# dio register map
Vendor: Texas Instruments
Peripheral module from a debugger description file (folder MSP432).
Registers are 16-bit, read-write, no defined reset value unless marked. A register's access mark holds for its fields unless they carry their own. Offsets are as the file gives them; lines under a group give offsets from that group; [hi:lo] are bit positions; {n}, {i} and the like mark numbered series; 'fields as' and 'values as' point back to an identical list; <NAME> marks a mode.

## DIO
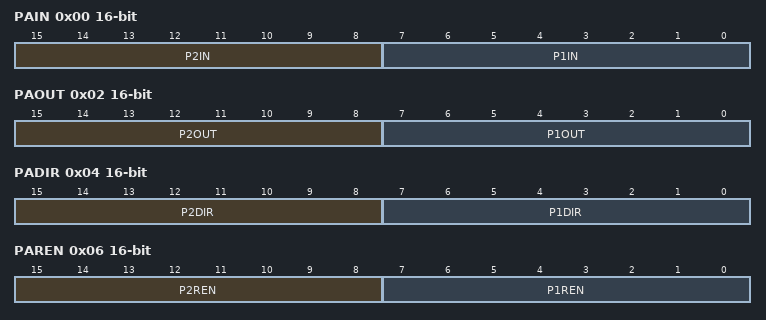
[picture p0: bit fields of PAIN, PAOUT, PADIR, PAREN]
0x00 PAIN — Port A Input
  [15:8] P2IN — Port 2 Input
  [7:0] P1IN — Port 1 Input
0x02 PAOUT — Port A Output
  [15:8] P2OUT — Port 2 Output
  [7:0] P1OUT — Port 1 Output
0x04 PADIR — Port A Direction
  [15:8] P2DIR — Port 2 Direction 0b = Port configured as input 1b = Port conf
  [7:0] P1DIR — Port 1 Direction 0b = Port configured as input 1b = Port conf
0x06 PAREN — Port A Resistor Enable
  [15:8] P2REN — Port 2 pullup or pulldown resistor enable
  [7:0] P1REN — Port 1 pullup or pulldown resistor enable
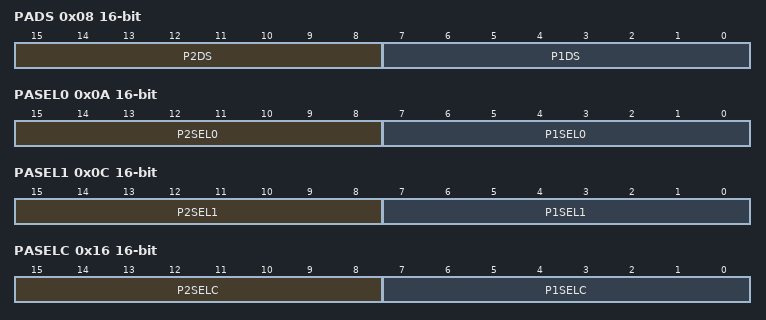
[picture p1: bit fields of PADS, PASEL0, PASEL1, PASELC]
0x08 PADS — Port A Drive Strength
  [15:8] P2DS — Port 2 drive strength selection (for high drive strength I/Os)
  [7:0] P1DS — Port 1 drive strength selection (for high drive strength I/Os)
0x0A PASEL0 — Port A Select 0
  [15:8] P2SEL0 — Port function selection
  [7:0] P1SEL0 — Port function selection
0x0C PASEL1 — Port A Select 1
  [15:8] P2SEL1 — Port function selection
  [7:0] P1SEL1 — Port function selection
0x0E P1IV — Port 1 Interrupt Vector Register
  [4:0] P1IV — Port 1 interrupt vector value
    0=P1IV__0 (No interrupt pending); 2=P1IV__2 (Interrupt Source: Port 1); 4=P1IV__4 (Interrupt Source: Port 1.1 interrupt; Interrupt Flag: P1IFG1); 6=P1IV__6 (Interrupt Source: Port 1.2 interrupt; Interrupt Flag: P1IFG2); 8=P1IV__8 (Interrupt Source: Port 1.3 interrupt; Interrupt Flag: P1IFG3); 10=P1IV__16 (Interrupt Source: Port 1.4 interrupt; Interrupt Flag: P1IFG4); 12=P1IV__18 (Interrupt Source: Port 1.5 interrupt; Interrupt Flag: P1IFG5); 14=P1IV__20 (Interrupt Source: Port 1.6 interrupt; Interrupt Flag: P1IFG6); 16=P1IV__22 (Interrupt Source: Port 1)
0x16 PASELC — Port A Complement Select
  [15:8] P2SELC — Port selection complement
  [7:0] P1SELC — Port selection complement
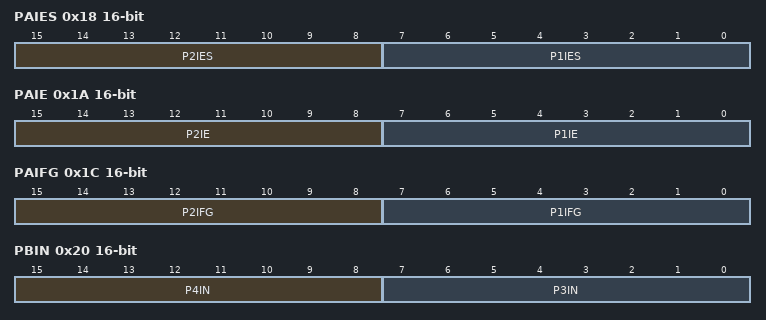
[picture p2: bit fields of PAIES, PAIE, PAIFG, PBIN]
0x18 PAIES — Port A Interrupt Edge Select
  [15:8] P2IES — Port 2 interrupt edge select 0b = PxIFG flag is set with a low
  [7:0] P1IES — Port 1 interrupt edge select 0b = PxIFG flag is set with a low
0x1A PAIE — Port A Interrupt Enable
  [15:8] P2IE — Port 2 Interrupt Enable 0b = Corresponding port interrupt disa
  [7:0] P1IE — Port 1 Interrupt Enable 0b = Corresponding port interrupt disa
0x1C PAIFG — Port A Interrupt Flag
  [15:8] P2IFG — Port 2 Interrupt Flag 0b = No interrupt is pending
  [7:0] P1IFG — Port 1 Interrupt Flag 0b = No interrupt is pending
0x1E P2IV — Port 2 Interrupt Vector Register
  [4:0] P2IV — Port 2 interrupt vector value
    0=P2IV__0 (No interrupt pending); 2=P2IV__2 (Interrupt Source: Port 2); 4=P2IV__4 (Interrupt Source: Port 2.1 interrupt; Interrupt Flag: P2IFG1); 6=P2IV__6 (Interrupt Source: Port 2.2 interrupt; Interrupt Flag: P2IFG2); 8=P2IV__8 (Interrupt Source: Port 2.3 interrupt; Interrupt Flag: P2IFG3); 10=P2IV__16 (Interrupt Source: Port 2.4 interrupt; Interrupt Flag: P2IFG4); 12=P2IV__18 (Interrupt Source: Port 2.5 interrupt; Interrupt Flag: P2IFG5); 14=P2IV__20 (Interrupt Source: Port 2.6 interrupt; Interrupt Flag: P2IFG6); 16=P2IV__22 (Interrupt Source: Port 2)
0x20 PBIN — Port B Input
  [15:8] P4IN — Port 4 Input
  [7:0] P3IN — Port 3 Input
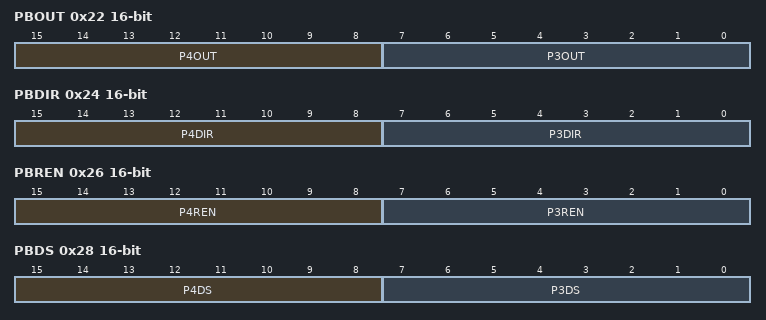
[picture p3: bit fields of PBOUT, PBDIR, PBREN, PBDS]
0x22 PBOUT — Port B Output
  [15:8] P4OUT — Port 4 Output
  [7:0] P3OUT — Port 3 Output
0x24 PBDIR — Port B Direction
  [15:8] P4DIR — Port 4 Direction 0b = Port configured as input 1b = Port conf
  [7:0] P3DIR — Port 3 Direction 0b = Port configured as input 1b = Port conf
0x26 PBREN — Port B Resistor Enable
  [15:8] P4REN — Port 4 pullup or pulldown resistor enable
  [7:0] P3REN — Port 3 pullup or pulldown resistor enable
0x28 PBDS — Port B Drive Strength
  [15:8] P4DS — Port 4 drive strength selection (for high drive strength I/Os)
  [7:0] P3DS — Port 3 drive strength selection (for high drive strength I/Os)
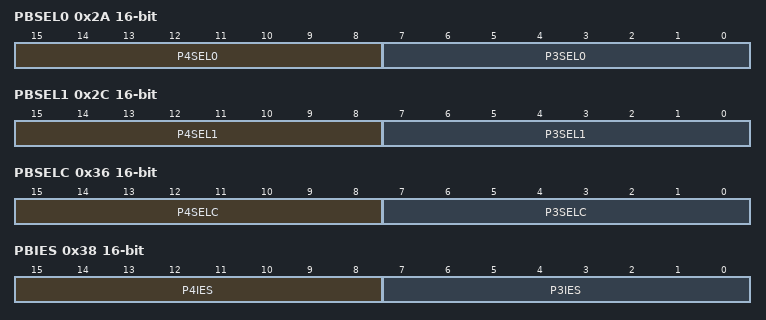
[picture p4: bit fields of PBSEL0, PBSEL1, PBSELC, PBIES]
0x2A PBSEL0 — Port B Select 0
  [15:8] P4SEL0 — Port function selection
  [7:0] P3SEL0 — Port function selection
0x2C PBSEL1 — Port B Select 1
  [15:8] P4SEL1 — Port function selection
  [7:0] P3SEL1 — Port function selection
0x2E P3IV — Port 3 Interrupt Vector Register
  [4:0] P3IV — Port 3 interrupt vector value
    0=P3IV__0 (No interrupt pending); 2=P3IV__2 (Interrupt Source: Port 3); 4=P3IV__4 (Interrupt Source: Port 3.1 interrupt; Interrupt Flag: P3IFG1); 6=P3IV__6 (Interrupt Source: Port 3.2 interrupt; Interrupt Flag: P3IFG2); 8=P3IV__8 (Interrupt Source: Port 3.3 interrupt; Interrupt Flag: P3IFG3); 10=P3IV__16 (Interrupt Source: Port 3.4 interrupt; Interrupt Flag: P3IFG4); 12=P3IV__18 (Interrupt Source: Port 3.5 interrupt; Interrupt Flag: P3IFG5); 14=P3IV__20 (Interrupt Source: Port 3.6 interrupt; Interrupt Flag: P3IFG6); 16=P3IV__22 (Interrupt Source: Port 3)
0x36 PBSELC — Port B Complement Select
  [15:8] P4SELC — Port selection complement
  [7:0] P3SELC — Port selection complement
0x38 PBIES — Port B Interrupt Edge Select
  [15:8] P4IES — Port 4 interrupt edge select 0b = PxIFG flag is set with a low
  [7:0] P3IES — Port 3 interrupt edge select 0b = PxIFG flag is set with a low
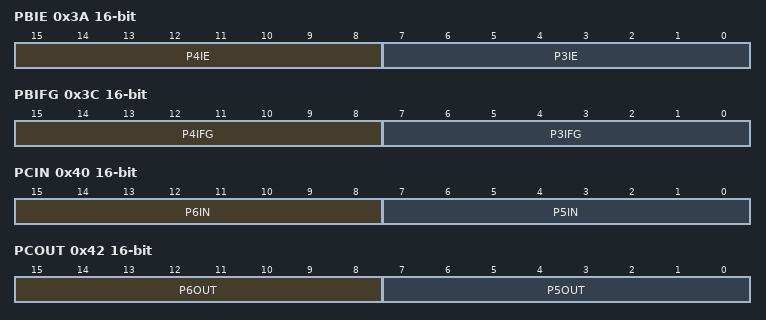
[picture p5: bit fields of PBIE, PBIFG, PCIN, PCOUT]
0x3A PBIE — Port B Interrupt Enable
  [15:8] P4IE — Port 4 Interrupt Enable 0b = Corresponding port interrupt disa
  [7:0] P3IE — Port 3 Interrupt Enable 0b = Corresponding port interrupt disa
0x3C PBIFG — Port B Interrupt Flag
  [15:8] P4IFG — Port 4 Interrupt Flag 0b = No interrupt is pending
  [7:0] P3IFG — Port 3 Interrupt Flag 0b = No interrupt is pending
0x3E P4IV — Port 4 Interrupt Vector Register
  [4:0] P4IV — Port 4 interrupt vector value
    0=P4IV__0 (No interrupt pending); 2=P4IV__2 (Interrupt Source: Port 4); 4=P4IV__4 (Interrupt Source: Port 4.1 interrupt; Interrupt Flag: P4IFG1); 6=P4IV__6 (Interrupt Source: Port 4.2 interrupt; Interrupt Flag: P4IFG2); 8=P4IV__8 (Interrupt Source: Port 4.3 interrupt; Interrupt Flag: P4IFG3); 10=P4IV__16 (Interrupt Source: Port 4.4 interrupt; Interrupt Flag: P4IFG4); 12=P4IV__18 (Interrupt Source: Port 4.5 interrupt; Interrupt Flag: P4IFG5); 14=P4IV__20 (Interrupt Source: Port 4.6 interrupt; Interrupt Flag: P4IFG6); 16=P4IV__22 (Interrupt Source: Port 4)
0x40 PCIN — Port C Input
  [15:8] P6IN — Port 6 Input
  [7:0] P5IN — Port 5 Input
0x42 PCOUT — Port C Output
  [15:8] P6OUT — Port 6 Output
  [7:0] P5OUT — Port 5 Output
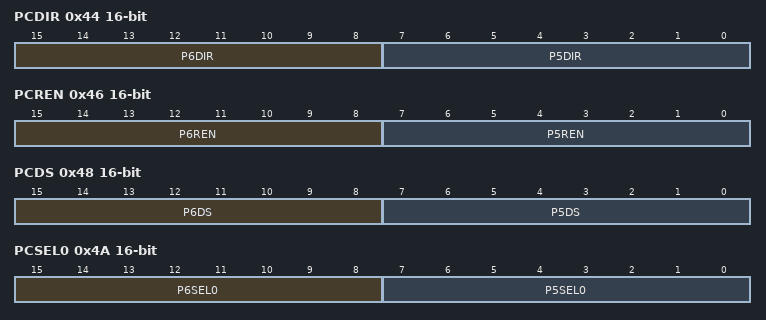
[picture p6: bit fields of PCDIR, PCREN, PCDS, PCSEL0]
0x44 PCDIR — Port C Direction
  [15:8] P6DIR — Port 6 Direction 0b = Port configured as input 1b = Port conf
  [7:0] P5DIR — Port 5 Direction 0b = Port configured as input 1b = Port conf
0x46 PCREN — Port C Resistor Enable
  [15:8] P6REN — Port 6 pullup or pulldown resistor enable
  [7:0] P5REN — Port 5 pullup or pulldown resistor enable
0x48 PCDS — Port C Drive Strength
  [15:8] P6DS — Port 6 drive strength selection (for high drive strength I/Os)
  [7:0] P5DS — Port 5 drive strength selection (for high drive strength I/Os)
0x4A PCSEL0 — Port C Select 0
  [15:8] P6SEL0 — Port function selection
  [7:0] P5SEL0 — Port function selection
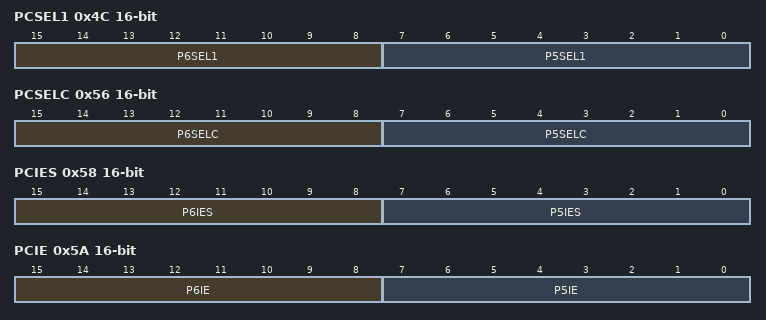
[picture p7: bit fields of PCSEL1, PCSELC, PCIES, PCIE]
0x4C PCSEL1 — Port C Select 1
  [15:8] P6SEL1 — Port function selection
  [7:0] P5SEL1 — Port function selection
0x4E P5IV — Port 5 Interrupt Vector Register
  [4:0] P5IV — Port 5 interrupt vector value
    0=P5IV__0 (No interrupt pending); 2=P5IV__2 (Interrupt Source: Port 5); 4=P5IV__4 (Interrupt Source: Port 5.1 interrupt; Interrupt Flag: P5IFG1); 6=P5IV__6 (Interrupt Source: Port 5.2 interrupt; Interrupt Flag: P5IFG2); 8=P5IV__8 (Interrupt Source: Port 5.3 interrupt; Interrupt Flag: P5IFG3); 10=P5IV__16 (Interrupt Source: Port 5.4 interrupt; Interrupt Flag: P5IFG4); 12=P5IV__18 (Interrupt Source: Port 5.5 interrupt; Interrupt Flag: P5IFG5); 14=P5IV__20 (Interrupt Source: Port 5.6 interrupt; Interrupt Flag: P5IFG6); 16=P5IV__22 (Interrupt Source: Port 5)
0x56 PCSELC — Port C Complement Select
  [15:8] P6SELC — Port selection complement
  [7:0] P5SELC — Port selection complement
0x58 PCIES — Port C Interrupt Edge Select
  [15:8] P6IES — Port 6 interrupt edge select 0b = PxIFG flag is set with a low
  [7:0] P5IES — Port 5 interrupt edge select 0b = PxIFG flag is set with a low
0x5A PCIE — Port C Interrupt Enable
  [15:8] P6IE — Port 6 Interrupt Enable 0b = Corresponding port interrupt disa
  [7:0] P5IE — Port 5 Interrupt Enable 0b = Corresponding port interrupt disa
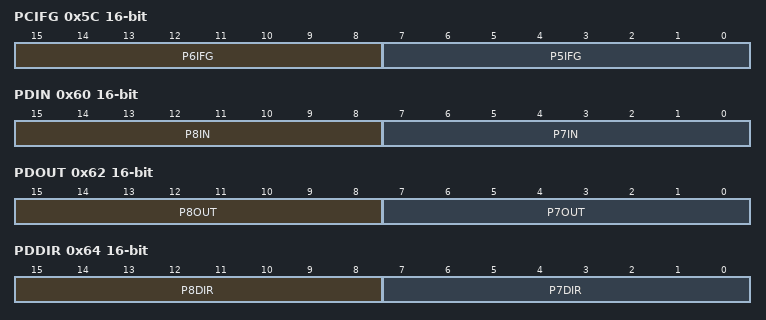
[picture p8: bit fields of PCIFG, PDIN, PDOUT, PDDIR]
0x5C PCIFG — Port C Interrupt Flag
  [15:8] P6IFG — Port 6 Interrupt Flag 0b = No interrupt is pending
  [7:0] P5IFG — Port 5 Interrupt Flag 0b = No interrupt is pending
0x5E P6IV — Port 6 Interrupt Vector Register
  [4:0] P6IV — Port 6 interrupt vector value
    0=P6IV__0 (No interrupt pending); 2=P6IV__2 (Interrupt Source: Port 6); 4=P6IV__4 (Interrupt Source: Port 6.1 interrupt; Interrupt Flag: P6IFG1); 6=P6IV__6 (Interrupt Source: Port 6.2 interrupt; Interrupt Flag: P6IFG2); 8=P6IV__8 (Interrupt Source: Port 6.3 interrupt; Interrupt Flag: P6IFG3); 10=P6IV__16 (Interrupt Source: Port 6.4 interrupt; Interrupt Flag: P6IFG4); 12=P6IV__18 (Interrupt Source: Port 6.5 interrupt; Interrupt Flag: P6IFG5); 14=P6IV__20 (Interrupt Source: Port 6.6 interrupt; Interrupt Flag: P6IFG6); 16=P6IV__22 (Interrupt Source: Port 6)
0x60 PDIN — Port D Input
  [15:8] P8IN — Port 8 Input
  [7:0] P7IN — Port 7 Input
0x62 PDOUT — Port D Output
  [15:8] P8OUT — Port 8 Output
  [7:0] P7OUT — Port 7 Output
0x64 PDDIR — Port D Direction
  [15:8] P8DIR — Port 8 Direction 0b = Port configured as input 1b = Port conf
  [7:0] P7DIR — Port 7 Direction 0b = Port configured as input 1b = Port conf
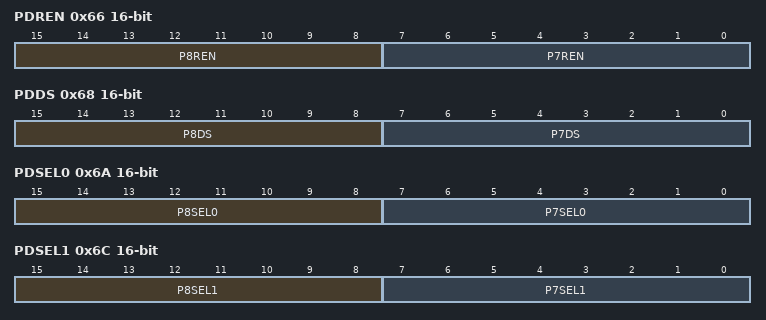
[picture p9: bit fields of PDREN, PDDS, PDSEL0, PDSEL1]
0x66 PDREN — Port D Resistor Enable
  [15:8] P8REN — Port 8 pullup or pulldown resistor enable
  [7:0] P7REN — Port 7 pullup or pulldown resistor enable
0x68 PDDS — Port D Drive Strength
  [15:8] P8DS — Port 8 drive strength selection (for high drive strength I/Os)
  [7:0] P7DS — Port 7 drive strength selection (for high drive strength I/Os)
0x6A PDSEL0 — Port D Select 0
  [15:8] P8SEL0 — Port function selection
  [7:0] P7SEL0 — Port function selection
0x6C PDSEL1 — Port D Select 1
  [15:8] P8SEL1 — Port function selection
  [7:0] P7SEL1 — Port function selection
0x6E P7IV — Port 7 Interrupt Vector Register
  [4:0] P7IV — Port 7 interrupt vector value
    0=P7IV__0 (No interrupt pending); 2=P7IV__2 (Interrupt Source: Port 7); 4=P7IV__4 (Interrupt Source: Port 7.1 interrupt; Interrupt Flag: P7IFG1); 6=P7IV__6 (Interrupt Source: Port 7.2 interrupt; Interrupt Flag: P7IFG2); 8=P7IV__8 (Interrupt Source: Port 7.3 interrupt; Interrupt Flag: P7IFG3); 10=P7IV__16 (Interrupt Source: Port 7.4 interrupt; Interrupt Flag: P7IFG4); 12=P7IV__18 (Interrupt Source: Port 7.5 interrupt; Interrupt Flag: P7IFG5); 14=P7IV__20 (Interrupt Source: Port 7.6 interrupt; Interrupt Flag: P7IFG6); 16=P7IV__22 (Interrupt Source: Port 7)
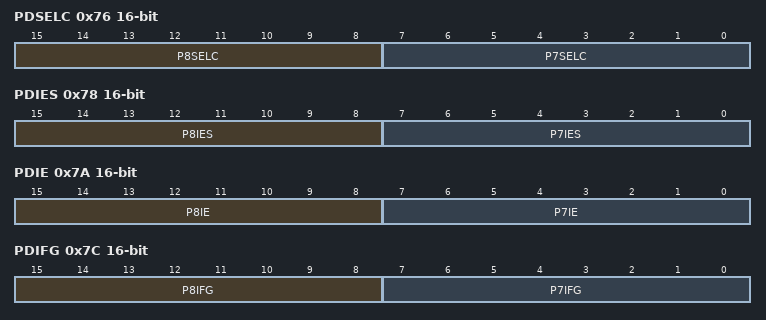
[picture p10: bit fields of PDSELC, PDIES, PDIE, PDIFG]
0x76 PDSELC — Port D Complement Select
  [15:8] P8SELC — Port selection complement
  [7:0] P7SELC — Port selection complement
0x78 PDIES — Port D Interrupt Edge Select
  [15:8] P8IES — Port 8 interrupt edge select 0b = PxIFG flag is set with a low
  [7:0] P7IES — Port 7 interrupt edge select 0b = PxIFG flag is set with a low
0x7A PDIE — Port D Interrupt Enable
  [15:8] P8IE — Port 8 Interrupt Enable 0b = Corresponding port interrupt disa
  [7:0] P7IE — Port 7 Interrupt Enable 0b = Corresponding port interrupt disa
0x7C PDIFG — Port D Interrupt Flag
  [15:8] P8IFG — Port 8 Interrupt Flag 0b = No interrupt is pending
  [7:0] P7IFG — Port 7 Interrupt Flag 0b = No interrupt is pending
0x7E P8IV — Port 8 Interrupt Vector Register
  [4:0] P8IV — Port 8 interrupt vector value
    0=P8IV__0 (No interrupt pending); 2=P8IV__2 (Interrupt Source: Port 8); 4=P8IV__4 (Interrupt Source: Port 8.1 interrupt; Interrupt Flag: P8IFG1); 6=P8IV__6 (Interrupt Source: Port 8.2 interrupt; Interrupt Flag: P8IFG2); 8=P8IV__8 (Interrupt Source: Port 8.3 interrupt; Interrupt Flag: P8IFG3); 10=P8IV__16 (Interrupt Source: Port 8.4 interrupt; Interrupt Flag: P8IFG4); 12=P8IV__18 (Interrupt Source: Port 8.5 interrupt; Interrupt Flag: P8IFG5); 14=P8IV__20 (Interrupt Source: Port 8.6 interrupt; Interrupt Flag: P8IFG6); 16=P8IV__22 (Interrupt Source: Port 8)
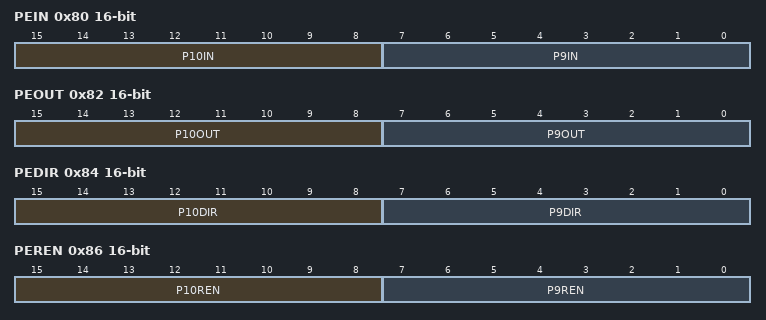
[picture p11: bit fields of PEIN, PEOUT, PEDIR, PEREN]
0x80 PEIN — Port E Input
  [15:8] P10IN — Port 10 Input
  [7:0] P9IN — Port 9 Input
0x82 PEOUT — Port E Output
  [15:8] P10OUT — Port 10 Output
  [7:0] P9OUT — Port 9 Output
0x84 PEDIR — Port E Direction
  [15:8] P10DIR — Port 10 Direction 0b = Port configured as input 1b = Port con
  [7:0] P9DIR — Port 9 Direction 0b = Port configured as input 1b = Port conf
0x86 PEREN — Port E Resistor Enable
  [15:8] P10REN — Port 10 pullup or pulldown resistor enable
  [7:0] P9REN — Port 9 pullup or pulldown resistor enable
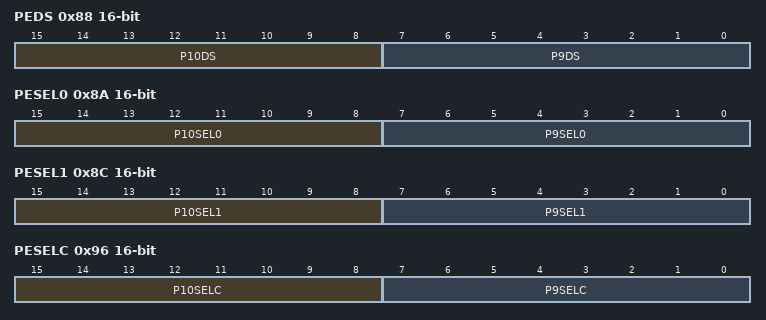
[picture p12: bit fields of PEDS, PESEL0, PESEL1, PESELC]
0x88 PEDS — Port E Drive Strength
  [15:8] P10DS — Port 10 drive strength selection (for high drive strength I/Os)
  [7:0] P9DS — Port 9 drive strength selection (for high drive strength I/Os)
0x8A PESEL0 — Port E Select 0
  [15:8] P10SEL0 — Port function selection
  [7:0] P9SEL0 — Port function selection
0x8C PESEL1 — Port E Select 1
  [15:8] P10SEL1 — Port function selection
  [7:0] P9SEL1 — Port function selection
0x8E P9IV — Port 9 Interrupt Vector Register
  [4:0] P9IV — Port 9 interrupt vector value
    0=P9IV__0 (No interrupt pending); 2=P9IV__2 (Interrupt Source: Port 9); 4=P9IV__4 (Interrupt Source: Port 9.1 interrupt; Interrupt Flag: P9IFG1); 6=P9IV__6 (Interrupt Source: Port 9.2 interrupt; Interrupt Flag: P9IFG2); 8=P9IV__8 (Interrupt Source: Port 9.3 interrupt; Interrupt Flag: P9IFG3); 10=P9IV__16 (Interrupt Source: Port 9.4 interrupt; Interrupt Flag: P9IFG4); 12=P9IV__18 (Interrupt Source: Port 9.5 interrupt; Interrupt Flag: P9IFG5); 14=P9IV__20 (Interrupt Source: Port 9.6 interrupt; Interrupt Flag: P9IFG6); 16=P9IV__22 (Interrupt Source: Port 9)
0x96 PESELC — Port E Complement Select
  [15:8] P10SELC — Port selection complement
  [7:0] P9SELC — Port selection complement
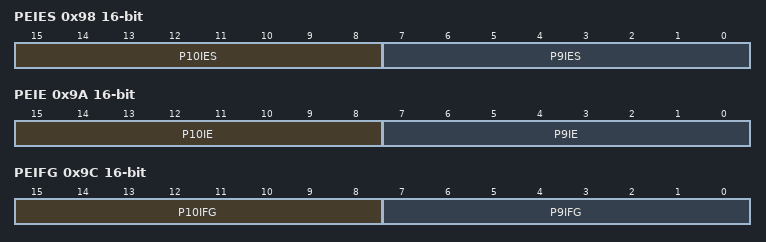
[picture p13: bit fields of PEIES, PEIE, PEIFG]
0x98 PEIES — Port E Interrupt Edge Select
  [15:8] P10IES — Port 10 interrupt edge select 0b = PxIFG flag is set with a lo
  [7:0] P9IES — Port 9 interrupt edge select 0b = PxIFG flag is set with a low
0x9A PEIE — Port E Interrupt Enable
  [15:8] P10IE — Port 10 Interrupt Enable 0b = Corresponding port interrupt dis
  [7:0] P9IE — Port 9 Interrupt Enable 0b = Corresponding port interrupt disa
0x9C PEIFG — Port E Interrupt Flag
  [15:8] P10IFG — Port 10 Interrupt Flag 0b = No interrupt is pending
  [7:0] P9IFG — Port 9 Interrupt Flag 0b = No interrupt is pending
0x9E P10IV — Port 10 Interrupt Vector Register
  [4:0] P10IV — Port 10 interrupt vector value
    0=P10IV__0 (No interrupt pending); 2=P10IV__2 (Interrupt Source: Port 10); 4=P10IV__4 (Interrupt Source: Port 10.1 interrupt; Interrupt Flag: P10IFG1); 6=P10IV__6 (Interrupt Source: Port 10.2 interrupt; Interrupt Flag: P10IFG2); 8=P10IV__8 (Interrupt Source: Port 10.3 interrupt; Interrupt Flag: P10IFG3); 10=P10IV__16 (Interrupt Source: Port 10.4 interrupt; Interrupt Flag: P10IFG4); 12=P10IV__18 (Interrupt Source: Port 10.5 interrupt; Interrupt Flag: P10IFG5); 14=P10IV__20 (Interrupt Source: Port 10.6 interrupt; Interrupt Flag: P10IFG6); 16=P10IV__22 (Interrupt Source: Port 10)
0x120 PJIN — Port J Input
0x122 PJOUT — Port J Output
0x124 PJDIR — Port J Direction
  [15:0] PJDIR — Port J Direction 0b = Port configured as input 1b = Port conf
0x126 PJREN — Port J Resistor Enable
  [15:0] PJREN — Port J pullup or pulldown resistor enable
0x128 PJDS — Port J Drive Strength
  [15:0] PJDS — Port J drive strength selection (for high drive strength I/Os)
0x12A PJSEL0 — Port J Select 0
  [15:0] PJSEL0 — Port function selection
0x12C PJSEL1 — Port J Select 1
  [15:0] PJSEL1 — Port function selection
0x136 PJSELC — Port J Complement Select
  [15:0] PJSELC — Port selection complement
